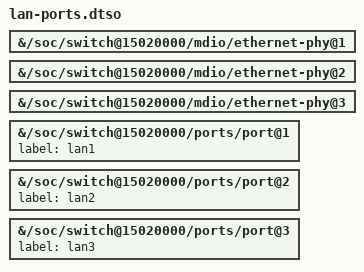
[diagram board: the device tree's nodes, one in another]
// SPDX-License-Identifier: (GPL-2.0 OR MIT)
/*
 * BPI-R4 Pro 4E: enable switch ports 1/2/3 as lan1/lan2/lan3.
 *
 * The mainline board dtsi (mt7988a-bananapi-bpi-r4-pro.dtsi) disables
 * gsw_phy1..3 and gsw_port1..3 with the comment "R4Pro has only port 0
 * connected".  This board is used as a cobalt site router and needs:
 *
 *   lan1  -> 802.1Q trunk into br-cobalt-lan
 *   lan2  -> access port, untagged (VLAN 30)
 *   lan3  -> access port, untagged (VLAN 30)
 *   lan5  -> management (untouched, still DHCP on its own netdev)
 *
 * So re-enable the three ports + their internal PHYs and give them stable
 * labels.  The SoC dtsi already defines the nodes (phy-mode "internal",
 * phy-handle wired); only status/label are changed here.
 *
 * This is a platform binding of realization mechanics (which physical port
 * carries which role) -- it adds no network meaning.
 */

/dts-v1/;
/plugin/;

&{/soc/switch@15020000/mdio/ethernet-phy@1} { status = "okay"; };
&{/soc/switch@15020000/mdio/ethernet-phy@2} { status = "okay"; };
&{/soc/switch@15020000/mdio/ethernet-phy@3} { status = "okay"; };

&{/soc/switch@15020000/ports/port@1} { status = "okay"; label = "lan1"; };
&{/soc/switch@15020000/ports/port@2} { status = "okay"; label = "lan2"; };
&{/soc/switch@15020000/ports/port@3} { status = "okay"; label = "lan3"; };
